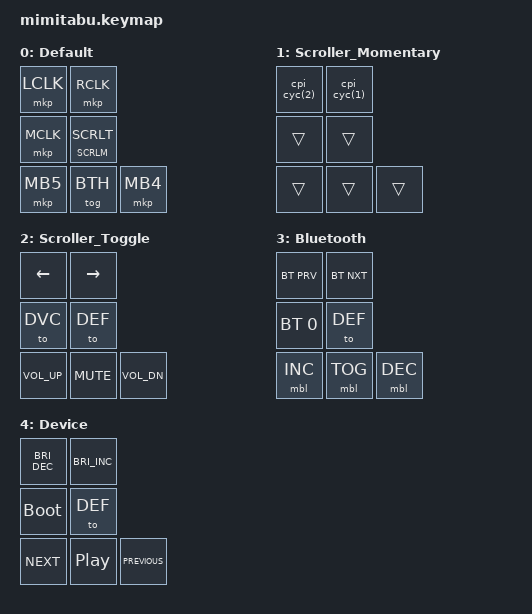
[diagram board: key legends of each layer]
#include <behaviors.dtsi>
#include <dt-bindings/zmk/bt.h>
#include <dt-bindings/zmk/keys.h>
#include <dt-bindings/zmk/pointing.h>
#include <dt-bindings/zmk/outputs.h>
#include <behaviors/rgbled_widget.dtsi>
#include <dt-bindings/zmk/backlight.h>

// layers
#define DEF 0 // default
#define SCRLM 1 // scroll_momentary
#define SCRLT 2 // scroll_toggle
#define BTH 3 // bluetooth
#define DVC 4 // device

/ {

  behaviors {
    mo_to: momentary-to-layer { // momentary on hold or to when tap
      compatible = "zmk,behavior-hold-tap";
      #binding-cells = <2>;
      hold-while-undecided;
      tapping-term-ms = <200>;
      bindings = <&mo>, <&to>;
    };
    // td_bth_dvc: tap_dance_bluetooth_device { // bluetooth layer when one tap, device layer when two taps
    //   compatible = "zmk,behavior-tap-dance";
    //   #binding-cells = <0>;
    //   tapping-term-ms = <300>;
    //   bindings = <&tog BTH>, <&tog DVC>;
    // };
    mbl: motbl {
      compatible = "zmk,behavior-input-motion-pwm";
      #binding-cells = <2>;
      display-name = "Motion Backlight";
    };
  };

  combos {
    compatible = "zmk,combos";
    combo_bt_clear { // clear bluetooth connection for seleted profile
      layers = <BTH>;
      key-positions = <2 3>;
      bindings = <&bt BT_CLR>;
    };
  };

  keymap {
    compatible = "zmk,keymap";
    default_layer {
      display-name = "Default";
      bindings = <
         &mkp LCLK &mkp RCLK
         &mkp MCLK &mo_to SCRLM SCRLT
         &mkp MB5 &tog BTH &mkp MB4
      >;
    };
    scroll_mo_layer {
      display-name = "Scroller_Momentary";
      bindings = <
        &cpi_cyc(2) &cpi_cyc(1)
        &trans &trans
        &trans &trans &trans
      >;
    };
    scroll_tog_layer {
      display-name = "Scroller_Toggle";
      bindings = <
        &kp LEFT_ARROW &kp RIGHT_ARROW
        &to DVC &to DEF
        &kp C_VOL_UP &kp C_MUTE &kp C_VOL_DN
      >;
    };
    bluetooth_layer {
      display-name = "Bluetooth";
      // tap two middle buttons, then current profile cleared
      bindings = <
        &bt BT_PRV &bt BT_NXT
        &bt BT_SEL 0 &to DEF 
        &mbl BL_INC &mbl BL_TOG &mbl BL_DEC
      >;
    };
    device_layer {
      display-name = "Device";
      bindings = <
        &kp C_BRI_DEC &kp C_BRI_INC
        &bootloader &to DEF
        &kp C_NEXT &kp C_PLAY_PAUSE &kp C_PREVIOUS
      >;
    };
  };
};
